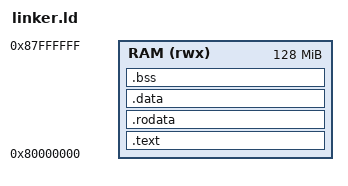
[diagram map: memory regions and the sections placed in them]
OUTPUT_ARCH(riscv)
ENTRY(_start)

MEMORY
{
    RAM (rwx) : ORIGIN = 0x80000000, LENGTH = 128M
}

SECTIONS
{
    .text : ALIGN(4)
    {
        KEEP(*(.text.init))
        *(.text .text.*)
    } > RAM

    .rodata : ALIGN(4)
    {
        *(.rodata .rodata.*)
        *(.srodata .srodata.*)
    } > RAM

    .data : ALIGN(4)
    {
        *(.data .data.*)
        *(.sdata .sdata.*)
    } > RAM

    .bss : ALIGN(4)
    {
        *(.bss .bss.*)
        *(.sbss .sbss.*)
        *(COMMON)
    } > RAM

    /*
     * Stack grows downward.
     * RAM = 0x80000000 .. 0x88000000
     */
    . = ALIGN(16);
    _stack_top = ORIGIN(RAM) + LENGTH(RAM);

    /DISCARD/ :
    {
        *(.comment)
        *(.note*)
        *(.eh_frame*)
        *(.riscv.attributes)
    }
}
